# STM32U599xx register map
File version: 1.0
Registers are 32-bit, read-write, reset 0x0 unless marked. A register's access mark holds for its fields unless they carry their own. Offsets are from the block's base; [hi:lo] are bit positions; {n}, {i} and the like mark numbered series.

## FLASH — FLASH Registers
Base 0x40022000
Same registers: FLASH_S 0x50022000
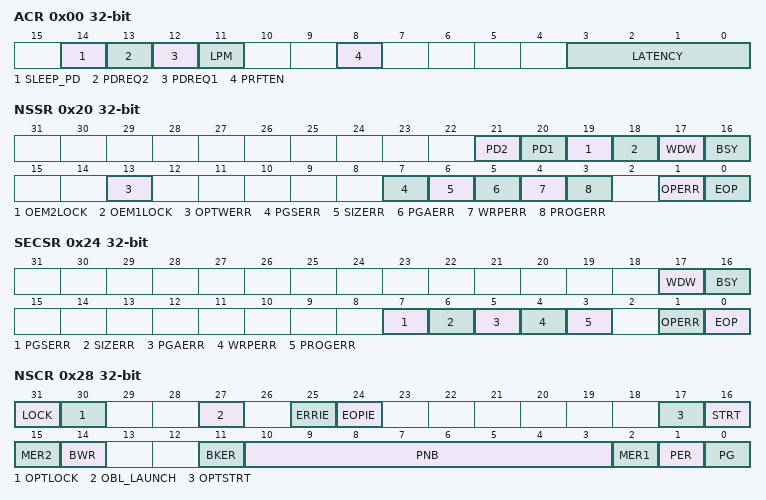
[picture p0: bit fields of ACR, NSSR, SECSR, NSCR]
0x00 ACR — FLASH access control register
  [14] SLEEP_PD — Flash power-down mode during sleep
  [13] PDREQ2 — Bank 2 power-down mode request
  [12] PDREQ1 — Bank 1 power-down mode request
  [11] LPM — Low-Power read mode
  [8] PRFTEN — Prefetch enable
  [3:0] LATENCY
    0=FLASH zero wait state; 1=FLASH one wait state; 2=FLASH two wait states; 3=FLASH three wait states; 4=FLASH four wait states; 5=FLASH five wait states; 6=FLASH six wait state; 7=FLASH Seven wait states; 8=FLASH Eight wait states; 9=FLASH nine wait states; 10=FLASH ten wait states; 11=FLASH eleven wait states; 12=FLASH twelve wait states; 13=FLASH thirteen wait states; 14=FLASH fourteen wait states; 15=FLASH fifteen wait states
0x08 NSKEYR — FLASH non-secure key register
0x0C SECKEYR — FLASH secure key register
0x10 OPTKEYR — FLASH option key register
0x18 PDKEY1R — FLASH Bank 1 power-down key register
0x1C PDKEY2R — FLASH Bank 2 power-down key register
0x20 NSSR — FLASH non-secure status register
  [21] PD2 — Bank 2 in power-down mode
  [20] PD1 — Bank 1 in power-down mode
  [19] OEM2LOCK
  [18] OEM1LOCK
  [17] WDW — Non-secure wait data to write
  [16] BSY — Non-secure busy
  [13] OPTWERR — Option write error
  [7] PGSERR — Non-secure programming sequence error
  [6] SIZERR — Non-secure size error
  [5] PGAERR — Non-secure programming alignment error
  [4] WRPERR — Non-secure write protection error
  [3] PROGERR — Non-secure programming error
  [1] OPERR — Non-secure operation error
  [0] EOP — Non-secure end of operation
0x24 SECSR — FLASH secure status register
  [17] WDW — Secure wait data to write
  [16] BSY — Secure busy
  [7] PGSERR — Secure programming sequence error
  [6] SIZERR — Secure size error
  [5] PGAERR — Secure programming alignment error
  [4] WRPERR — Secure write protection error
  [3] PROGERR — Secure programming error
  [1] OPERR — Secure operation error
  [0] EOP — Secure end of operation
0x28 NSCR — FLASH non-secure control register
  [31] LOCK — Non-secure Lock
  [30] OPTLOCK — Option Lock
  [27] OBL_LAUNCH — Force the option byte loading
  [25] ERRIE — Non-secure error interrupt enable
  [24] EOPIE — Non-secure End of operation interrupt enable
  [17] OPTSTRT — Option Modification Start
  [16] STRT — Non-secure Start
  [15] MER2 — Non-secure Bank 2 Mass Erase
  [14] BWR — Non-secure Burst Write Programming mode
  [11] BKER — Non-secure Bank Selection for Page Erase
  [10:3] PNB — Non-secure Page Number selection
  [2] MER1 — Non-secure Bank 1 Mass Erase
  [1] PER — Non-secure Page Erase
  [0] PG — Non-secure Programming
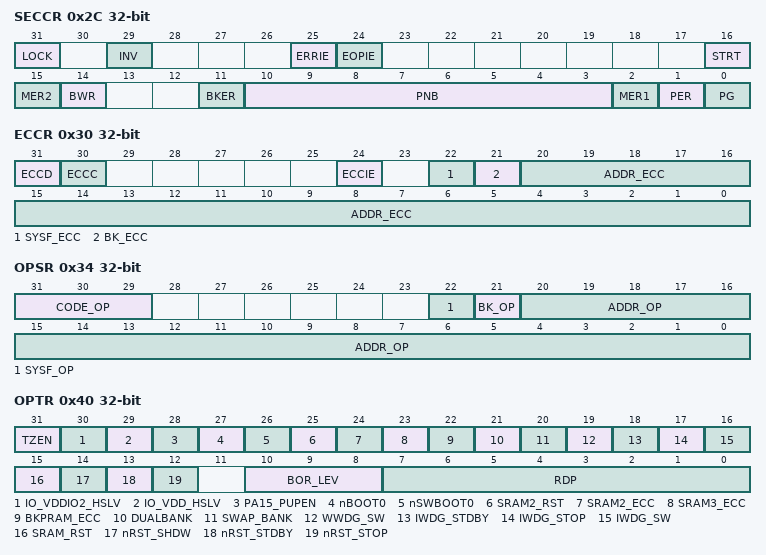
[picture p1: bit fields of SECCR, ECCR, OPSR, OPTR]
0x2C SECCR — FLASH secure control register
  [31] LOCK — Secure Lock
  [29] INV — Flash Security State Invert
  [25] ERRIE — Secure error interrupt enable
  [24] EOPIE — Secure end of operation interrupt enable
  [16] STRT — Secure Start
  [15] MER2 — Secure Bank 2 Mass Erase
  [14] BWR — Secure Burst Write programming mode
  [11] BKER — Secure Bank Selection for Page Erase
  [10:3] PNB — Secure Page Number selection
  [2] MER1 — Secure Bank 1 Mass Erase
  [1] PER — Secure Page Erase
  [0] PG — Secure Programming
0x30 ECCR — FLASH ECC register
  [31] ECCD — ECC detection
  [30] ECCC — ECC correction
  [24] ECCIE — ECC correction interrupt enable
  [22] SYSF_ECC — System Flash ECC fail
  [21] BK_ECC — ECC fail bank
  [20:0] ADDR_ECC — ECC fail address
0x34 OPSR — FLASH OPSR register
  [31:29] CODE_OP — Flash operation code
  [22] SYSF_OP — Operation in System Flash interrupted
  [21] BK_OP — Interrupted operation bank
  [20:0] ADDR_OP — Flash operation address
0x40 OPTR — FLASH option control register
  [31] TZEN — Global TrustZone security enable
  [30] IO_VDDIO2_HSLV — High speed IO at low VDDIO2 voltage configuration bit
  [29] IO_VDD_HSLV — High speed IO at low voltage configuration bit
  [28] PA15_PUPEN — PA15 pull-up enable
  [27] nBOOT0 — nBOOT0 option bit
  [26] nSWBOOT0 — Software BOOT0
  [25] SRAM2_RST — SRAM2 erase when system reset
  [24] SRAM2_ECC — SRAM2 ECC detection and correction enable
  [23] SRAM3_ECC — SRAM3 ECC detection and correction enable
  [22] BKPRAM_ECC — Backup RAM ECC detection and correction enable
  [21] DUALBANK — Dual-bank on 1M and 512 Kbytes Flash memory devices
  [20] SWAP_BANK — Swap banks
  [19] WWDG_SW — Window watchdog selection
  [18] IWDG_STDBY — Independent watchdog counter freeze in Standby mode
  [17] IWDG_STOP — Independent watchdog counter freeze in Stop mode
  [16] IWDG_SW — Independent watchdog selection
  [15] SRAM_RST — All SRAMs (except SRAM2 and BKPSRAM) erase upon system reset
  [14] nRST_SHDW
  [13] nRST_STDBY
  [12] nRST_STOP
  [10:8] BOR_LEV — BOR reset Level
  [7:0] RDP — Readout protection level
0x44 NSBOOTADD0R — FLASH non-secure boot address 0 register
  [31:7] NSBOOTADD0 — Non-secure boot address 0
0x48 NSBOOTADD1R — FLASH non-secure boot address 1 register
  [31:7] NSBOOTADD1 — Non-secure boot address 1
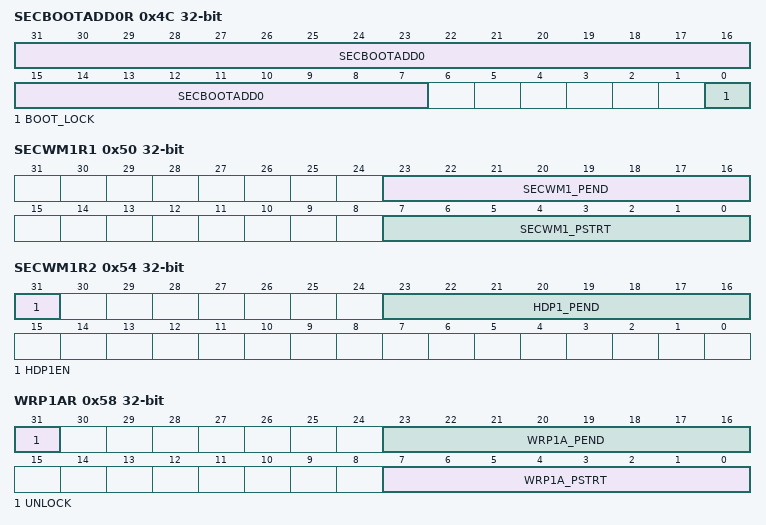
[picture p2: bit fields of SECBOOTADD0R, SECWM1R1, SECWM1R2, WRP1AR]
0x4C SECBOOTADD0R — FLASH secure boot address 0 register
  [31:7] SECBOOTADD0 — Secure boot address 0
  [0] BOOT_LOCK
0x50 SECWM1R1 — FLASH secure watermark1 register 1
  [23:16] SECWM1_PEND — End page of first secure area
  [7:0] SECWM1_PSTRT — Start page of first secure area
0x54 SECWM1R2 — FLASH secure watermark1 register 2
  [31] HDP1EN — Hide protection first area enable
  [23:16] HDP1_PEND — End page of first hide protection area
0x58 WRP1AR — FLASH WRP1 area A address register
  [31] UNLOCK — Bank 1 WPR first area A unlock
  [23:16] WRP1A_PEND — Bank 1 WPR first area A end page
  [7:0] WRP1A_PSTRT — Bank 1 WPR first area A start page
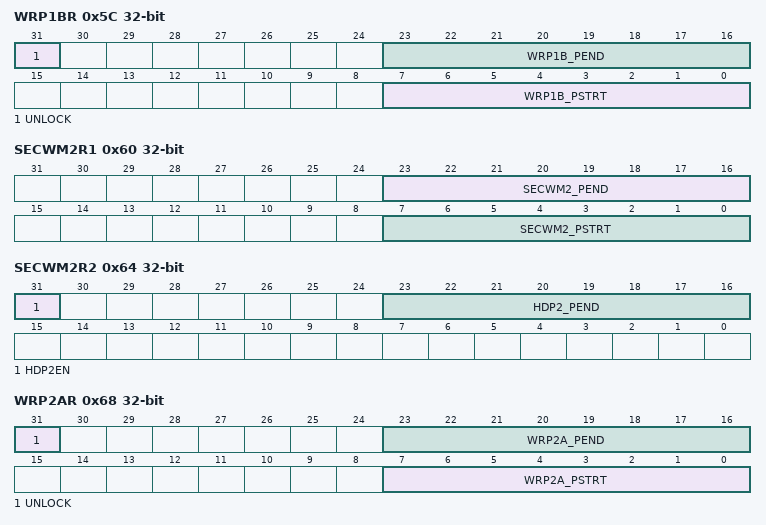
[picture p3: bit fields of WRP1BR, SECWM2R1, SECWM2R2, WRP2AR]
0x5C WRP1BR — FLASH WRP1 area B address register
  [31] UNLOCK — Bank 1 WPR first area B unlock
  [23:16] WRP1B_PEND — Bank 1 WPR second area B end page
  [7:0] WRP1B_PSTRT — Bank 1 WPR second area B start page
0x60 SECWM2R1 — FLASH secure watermark2 register 1
  [23:16] SECWM2_PEND — End page of second secure area
  [7:0] SECWM2_PSTRT — Start page of second secure area
0x64 SECWM2R2 — FLASH secure watermark2 register 2
  [31] HDP2EN — Hide protection second area enable
  [23:16] HDP2_PEND — End page of hide protection second area
0x68 WRP2AR — FLASH WRP2 area A address register
  [31] UNLOCK — Bank 2 WPR first area A unlock
  [23:16] WRP2A_PEND — Bank 2 WPR first area A end page
  [7:0] WRP2A_PSTRT — Bank 2 WPR first area A start page
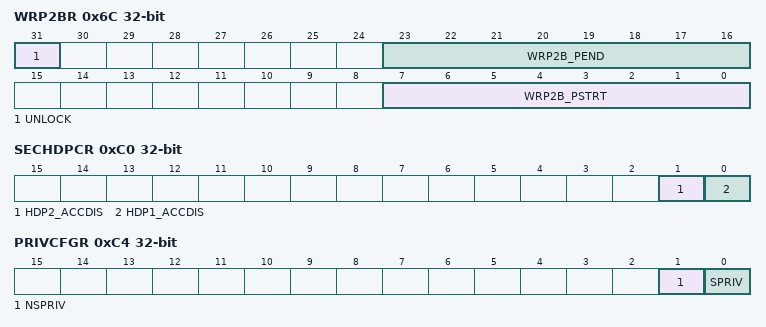
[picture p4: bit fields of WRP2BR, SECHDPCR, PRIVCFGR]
0x6C WRP2BR — FLASH WRP2 area B address register
  [31] UNLOCK — Bank 2 WPR first area B unlock
  [23:16] WRP2B_PEND — Bank 2 WPR first area B end page
  [7:0] WRP2B_PSTRT — Bank 2 WPR first area B start page
0x70 OEM1KEYR1 — FLASH OEM1 key register 1
0x74 OEM1KEYR2 — FLASH OEM1 key register 2
0x78 OEM2KEYR1 — FLASH OEM2 key register 1
0x7C OEM2KEYR2 — FLASH OEM2 key register 2
{0x7C+4i} SECBB1R{i} (i=1..8) — FLASH secure block-based bank 1 register {i}
{0x9C+4i} SECBB2R{i} (i=1..8) — FLASH secure block-based bank 2 register {i}
0xC0 SECHDPCR — FLASH secure HDP control register
  [1] HDP2_ACCDIS — HDP2 area access disable
  [0] HDP1_ACCDIS — HDP1 area access disable
0xC4 PRIVCFGR — FLASH privilege configuration register
  [1] NSPRIV — Privilege protection for non-secure registers
  [0] SPRIV — Privilege protection for secure registers
{0xCC+4i} PRIVBB1R{i} (i=1..8) — FLASH privilege block-based bank 1 register {i}
{0xEC+4i} PRIVBB2R{i} (i=1..8) — FLASH privilege block-based bank 2 register {i}
